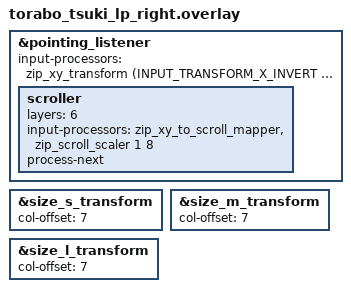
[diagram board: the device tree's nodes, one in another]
#include "torabo_tsuki_lp.dtsi"
#include <input/processors.dtsi>
#include <dt-bindings/zmk/input_transform.h>

/* トラックボール周り */
&pointing_listener {
    /* 方向反転だけ（元からあった設定） */
    input-processors =
        <&zip_xy_transform (INPUT_TRANSFORM_X_INVERT | INPUT_TRANSFORM_Y_INVERT)>;

    /* layer_6 のときだけスクロールに変換 */
    scroller {
        layers = <6>;
        input-processors =
            <&zip_xy_to_scroll_mapper>,
            <&zip_scroll_scaler 1 8>;
        process-next;
    };
};

&size_s_transform {
    col-offset = <7>;
};

&size_m_transform {
    col-offset = <7>;
};

&size_l_transform {
    col-offset = <7>;
};
